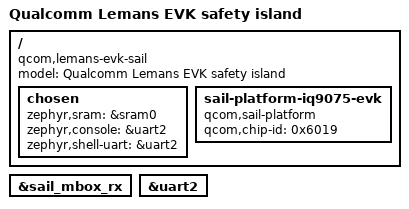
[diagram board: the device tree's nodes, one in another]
/*
 * Copyright The Zephyr Project Contributors
 * SPDX-License-Identifier: Apache-2.0
 */

/dts-v1/;
#include <qcom/sail-lemans.dtsi>

/ {
	compatible = "qcom,lemans-evk-sail";
	model = "Qualcomm Lemans EVK safety island";

	chosen {
		zephyr,sram = &sram0;
		zephyr,console = &uart2;
		zephyr,shell-uart = &uart2;
	};

	/* SAIL runs from the main-domain PMICs; it has no PMIC of its own. */
	sail-platform-iq9075-evk {
		compatible = "qcom,sail-platform";
		qcom,chip-id = <0x6019>;
	};
};

&sail_mbox_rx {
	status = "okay";
};

&uart2 {
	status = "okay";
};
